# MDR1206AFI register map
Vendor: Milandr; File version: 2.0
CPU: BM-310S0, little endian
Registers are 32-bit, read-write, reset 0x0 unless marked. A register's access mark holds for its fields unless they carry their own. Offsets are from the block's base; [hi:lo] are bit positions; {n}, {i} and the like mark numbered series; 'fields as' and 'values as' point back to an identical list.

## UART1 — UART1 Controller
Base 0x50008000
Same registers: UART2 0x50010000, UART3 0x50038000, UART4 0x500E8000
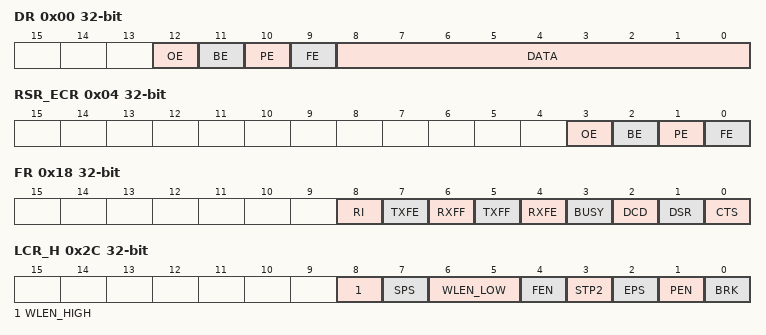
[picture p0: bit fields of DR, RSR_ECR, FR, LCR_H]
0x00 DR — Data Register
  [12] OE — Overrun error
    0=NO_OVERR_ERR (No overrun error was detected); 1=OVERRUN_ERR (Data is received and the receive FIFO is already full)
  [11] BE — Break error
    0=NO_BREAK_ERR (No break was detected); 1=BREAK_ERR (A break condition was detected)
  [10] PE — Parity error
    0=PAR_NO_ERR (Parity error has not been discovered); 1=PAR_ERR (The parity of the received data character doesn't correspond to the settings of the EPS and SPS bits in the LCR_H register)
  [9] FE — Framing error
    0=STOP_BIT_OK (Stop bit has been received correctly); 1=STOP_BIT_ERR (The received character did not have a valid stop bit()
  [8:0] DATA — Receive/transmit data
0x04 RSR_ECR — Receive Status Register/Error Clear Register
  [3] OE — Overrun error
    values as DR.OE
  [2] BE — Break error
    values as DR.BE
  [1] PE — Parity error
    values as DR.PE
  [0] FE — Framing error
    0=STOP_BIT_OK (Stop bit has been received correctly); 1=STOP_BIT_ERR (The received character doesn't have a valid stop bit ()
0x18 FR ro — Flag Register
  [8] RI — Inverted state of nUARTRI
  [7] TXFE — Transmit FIFO empty
  [6] RXFF — Receive FIFO full
  [5] TXFF — Transmit FIFO full
  [4] RXFE — Receive FIFO empty
  [3] BUSY — UART TX busy
    0=UART_TX_READY (The UART transmitter is free); 1=UART_TX_BUSY (The UART is busy transmitting data)
  [2] DCD — Inverted state of nUARTDCD
  [1] DSR — Inverted state of nUARTDSR
  [0] CTS — Inverted state of nUARTCTS
0x20 ILPR — IrDA Low-Power Counter Register
  [7:0] ILPDVSR — Low-power divisor
0x24 IBRD — Integer baud rate register
  [15:0] BAUDDIV_INT — Integer baud rate divisor
0x28 FBRD — Fractional baud rate register
  [5:0] BAUDDIV_FRAC — Fractional baud rate divisor
0x2C LCR_H — Line control register
  [8] WLEN_HIGH — Word length (WLEN[2])
    0=WLEN_5_8 (The number of data bits is defined by WLEN[1:0]); 1=WLEN_9 (The word length is 9 bits)
  [7] SPS — Stick parity select
  [6:5] WLEN_LOW — Word length (WLEN[1:0])
    {v}=WLEN_{v+5} ({v+5} bits) (v=0..3)
  [4] FEN — Enable FIFOs
  [3] STP2 — Two stop bits select
    0=STOP_BITS_1 (One stop bit is transmitted at the end of the frame); 1=STOP_BITS_2 (Two stop bits are transmitted at the end of the frame)
  [2] EPS — Even parity select
    0=ODD_PARITY (The UART generates or checks for an odd number of 1s in the data and parity bits); 1=EVEN_PARITY (The UART generates or checks for an even number of 1s in the data and parity bits)
  [1] PEN — Parity enable
    0=PAR_DISABLE (No parity bit added to the data frame); 1=PAR_ENABLE (A parity bit is added to the frame and is checked when received)
  [0] BRK — Send break
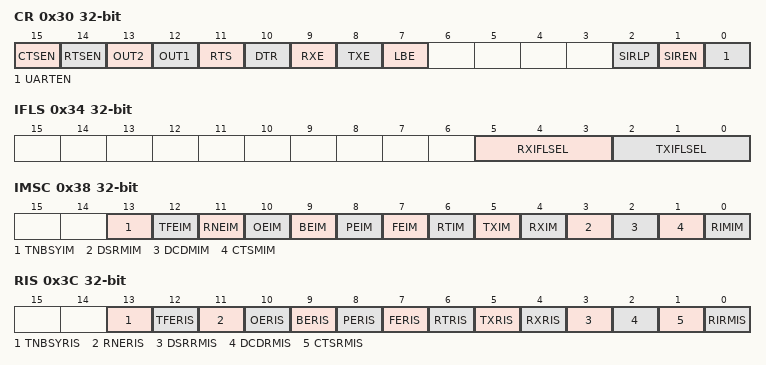
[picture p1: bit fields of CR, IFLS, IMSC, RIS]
0x30 CR — Control Register
  [15] CTSEN — CTS hardware flow control enable
    0=CTS_DISABLED (The control of nUARTCTS signal is disabled); 1=CTS_ENABLED (CTS hardware flow control is enabled. Data is only transmitted when the nUARTCTS signal is asserted)
  [14] RTSEN — RTS hardware flow control enable
    0=RTS_DISABLED (The control of nUARTRTS signal is disabled); 1=RTS_ENABLED (RTS hardware flow control is enabled. Data is only requested when there is space in the receive FIFO for it to be received)
  [13] OUT2 — Inverted state of nUARTOut2
  [12] OUT1 — Inverted state of nUARTOut1
  [11] RTS — Inverted state of nUARTRTS
  [10] DTR — Inverted state of nUARTDTR
  [9] RXE — Receive enable
  [8] TXE — Transmit enable
  [7] LBE — Loop back enable
  [2] SIRLP — IrDA SIR low power mode
  [1] SIREN — SIR enable
  [0] UARTEN — UART enable
0x34 IFLS — Interrupt FIFO level select register
  [5:3] RXIFLSEL — Receive FIFO Level Select
    0=RXF_LVL_1F8 (Receive FIFO becomes ≥ 1/8 full); 1=RXF_LVL_1F4 (Receive FIFO becomes ≥ 1/4 full); 2=RXF_LVL_1F2 (Receive FIFO becomes ≥ 1/2 full); 3=RXF_LVL_3F4 (Receive FIFO becomes ≥ 3/4 full); 4=RXF_LVL_7F8 (Receive FIFO becomes ≥ 7/8 full)
  [2:0] TXIFLSEL — Transmit FIFO level select
    0=TXF_LVL_1F8 (Transmit FIFO becomes ≤ 1/8 full); 1=TXF_LVL_1F4 (Transmit FIFO becomes ≤ 1/4 full); 2=TXF_LVL_1F2 (Transmit FIFO becomes ≤ 1/2 full); 3=TXF_LVL_3F4 (Transmit FIFO becomes ≤ 3/4 full); 4=TXF_LVL_7F8 (Transmit FIFO becomes ≤ 7/8 full)
0x38 IMSC — Interrupt mask set/clear register
  [13] TNBSYIM — Transmit shift register empty interrupt mask
  [12] TFEIM — Transmit FIFO empty interrupt mask
  [11] RNEIM — Receive FIFO not empty interrupt mask
  [10] OEIM — Receive FIFO overrun interrupt mask
  [9] BEIM — Break error interrupt mask
  [8] PEIM — Parity error interrupt mask
  [7] FEIM — Framing error interrupt mask
  [6] RTIM — Receive timeout interrupt mask
  [5] TXIM — Transmit interrupt mask
  [4] RXIM — Receive interrupt mask
  [3] DSRMIM — nUARTDSR modem interrupt mask
  [2] DCDMIM — nUARTDCD modem interrupt mask
  [1] CTSMIM — nUARTCTS modem interrupt mask
  [0] RIMIM — nUARTRI modem interrupt mask
0x3C RIS ro — Raw interrupt status register
  [13] TNBSYRIS — Transmit shift register empty interrupt status
  [12] TFERIS — Transmit FIFO empty interrupt status
  [11] RNERIS — Receive FIFO not empty interrupt status
  [10] OERIS — Receive FIFO overrun interrupt status
  [9] BERIS — Break error interrupt status
  [8] PERIS — Parity error interrupt status
  [7] FERIS — Framing error interrupt status
  [6] RTRIS — Receive timeout interrupt status
  [5] TXRIS — Transmit interrupt status
  [4] RXRIS — Receive interrupt status
  [3] DSRRMIS — nUARTDSR modem interrupt status
  [2] DCDRMIS — nUARTDCD modem interrupt status
  [1] CTSRMIS — nUARTCTS modem interrupt status
  [0] RIRMIS — nUARTRI modem interrupt status
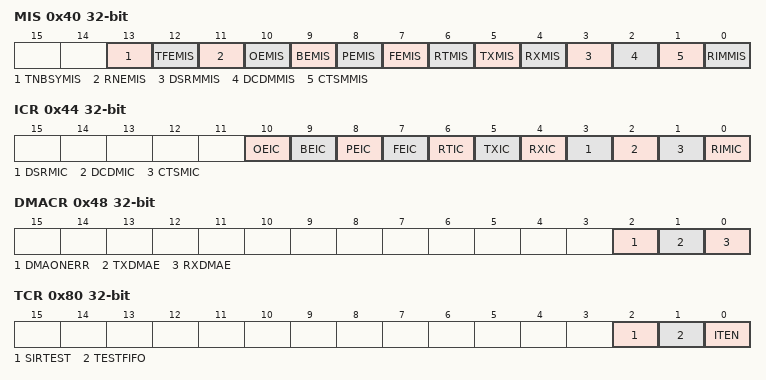
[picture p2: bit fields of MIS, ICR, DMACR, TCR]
0x40 MIS ro — Masked interrupt status register
  [13] TNBSYMIS — Transmit shift register empty masked interrupt status
  [12] TFEMIS — Transmit FIFO empty masked interrupt status
  [11] RNEMIS — Receive FIFO not empty masked interrupt status
  [10] OEMIS — Receive FIFO overrun masked interrupt status
  [9] BEMIS — Break error masked interrupt status
  [8] PEMIS — Parity error masked interrupt status
  [7] FEMIS — Framing error masked interrupt status
  [6] RTMIS — Receive timeout masked interrupt status
  [5] TXMIS — Transmit masked interrupt status
  [4] RXMIS — Receive masked interrupt status
  [3] DSRMMIS — nUARTDSR modem masked interrupt status
  [2] DCDMMIS — nUARTDCD modem masked interrupt status
  [1] CTSMMIS — nUARTCTS modem masked interrupt status
  [0] RIMMIS — nUARTRI modem masked interrupt status
0x44 ICR wo — Interrupt clear register
  [10] OEIC — Receive FIFO overrun interrupt clear
  [9] BEIC — Break error interrupt clear
  [8] PEIC — Parity error interrupt clear
  [7] FEIC — Framing error interrupt clear
  [6] RTIC — Receive timeout interrupt clear
  [5] TXIC — Transmit interrupt clear
  [4] RXIC — Receive interrupt clear
  [3] DSRMIC — nUARTDSR modem interrupt clear
  [2] DCDMIC — nUARTDCD modem interrupt clear
  [1] CTSMIC — nUARTCTS modem interrupt clear
  [0] RIMIC — nUARTRI modem interrupt clear
0x48 DMACR — DMA control register
  [2] DMAONERR — DMA on error
  [1] TXDMAE — Transmit DMA enable
  [0] RXDMAE — Receive DMA enable
0x80 TCR — Test control register
  [2] SIRTEST — SIR test enable
  [1] TESTFIFO — Test FIFO enable
  [0] ITEN — Integration test enable
